VERSION ""

NS_ :

BS_:

BU_: Device Host
VAL_TABLE_ Target 0 "Other" 1 "Debug" 2 "Release" 3 "Not Available" ;
VAL_TABLE_ vtCcpExtension 1 "CcpBatchTransfer" 15 "CcpExtensionNone" ;
VAL_TABLE_ vtOnOff 0 "Off" 1 "On" 2 "Error" 3 "Not available" ;

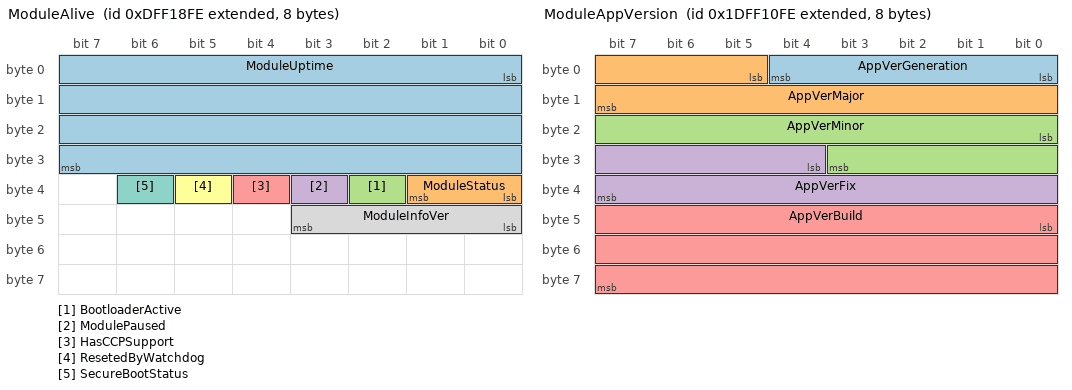
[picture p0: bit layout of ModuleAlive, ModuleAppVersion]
BO_ 2382305534 ModuleAlive: 8 Device
 SG_ ModuleUptime : 0|32@1+ (1,0) [0|4294967295] "s" Vector__XXX
 SG_ ModuleStatus : 32|2@1+ (1,0) [0|3] "" Vector__XXX
 SG_ BootloaderActive : 34|1@1+ (1,0) [0|0] "" Vector__XXX
 SG_ ModulePaused : 35|1@1+ (1,0) [0|0] "" Vector__XXX
 SG_ HasCCPSupport : 36|1@1+ (1,0) [0|0] "" Vector__XXX
 SG_ ResetedByWatchdog : 37|1@1+ (1,0) [0|1] "" Vector__XXX
 SG_ SecureBootStatus : 38|1@1+ (1,0) [0|1] "" Vector__XXX
 SG_ ModuleInfoVer : 40|4@1+ (1,0) [0|15] "" Vector__XXX

BO_ 2650739966 ModuleAppName1: 8 Device
 SG_ AppName1 : 0|64@1+ (1,0) [0|0] "" Vector__XXX

BO_ 2650740222 ModuleAppName2: 8 Device
 SG_ AppName2 : 0|64@1+ (1,0) [0|0] "" Vector__XXX

BO_ 2650738942 ModuleAppVersion: 8 Device
 SG_ AppVerGeneration : 0|5@1+ (1,0) [0|31] "" Vector__XXX
 SG_ AppVerMajor : 5|11@1+ (1,0) [0|2047] "" Vector__XXX
 SG_ AppVerMinor : 16|12@1+ (1,0) [0|4095] "" Vector__XXX
 SG_ AppVerFix : 28|12@1+ (1,0) [0|4090] "" Vector__XXX
 SG_ AppVerBuild : 40|24@1+ (1,0) [0|16777215] "" Vector__XXX

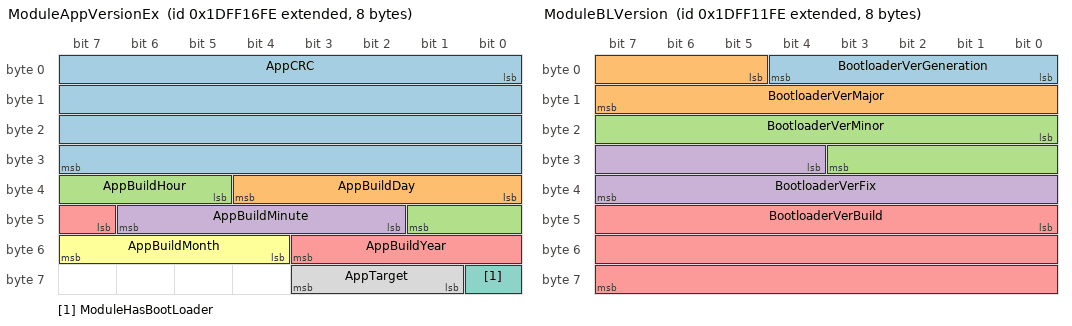
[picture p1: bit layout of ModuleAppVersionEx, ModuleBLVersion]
BO_ 2650740478 ModuleAppVersionEx: 8 Device
 SG_ AppCRC : 0|32@1+ (1,0) [0|0] "" Vector__XXX
 SG_ AppBuildDay : 32|5@1+ (1,0) [0|0] "" Vector__XXX
 SG_ AppBuildHour : 37|5@1+ (1,0) [0|0] "" Vector__XXX
 SG_ AppBuildMinute : 42|5@1+ (2,0) [0|0] "" Vector__XXX
 SG_ AppBuildYear : 47|5@1+ (1,2019) [0|0] "" Vector__XXX
 SG_ AppBuildMonth : 52|4@1+ (1,0) [0|0] "" Vector__XXX
 SG_ ModuleHasBootLoader : 56|1@1+ (1,0) [0|0] "" Vector__XXX
 SG_ AppTarget : 57|3@1+ (1,0) [0|0] "" Vector__XXX

BO_ 2650742014 ModuleBLName1: 8 Device
 SG_ BootloaderName1 : 0|64@1+ (1,0) [0|0] "" Vector__XXX

BO_ 2650741246 ModuleBLName2: 8 Device
 SG_ BootloaderName2 : 0|64@1+ (1,0) [0|0] "" Vector__XXX

BO_ 2650739198 ModuleBLVersion: 8 Device
 SG_ BootloaderVerGeneration : 0|5@1+ (1,0) [0|31] "" Vector__XXX
 SG_ BootloaderVerMajor : 5|11@1+ (1,0) [0|2047] "" Vector__XXX
 SG_ BootloaderVerMinor : 16|12@1+ (1,0) [0|4095] "" Vector__XXX
 SG_ BootloaderVerFix : 28|12@1+ (1,0) [0|4090] "" Vector__XXX
 SG_ BootloaderVerBuild : 40|24@1+ (1,0) [0|16777215] "" Vector__XXX

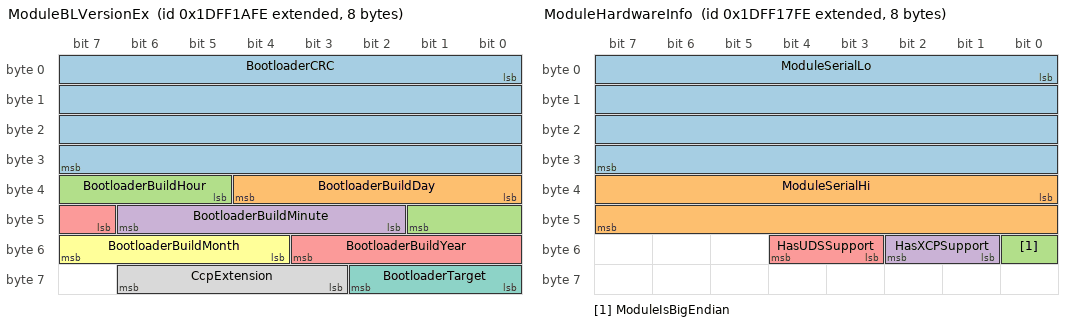
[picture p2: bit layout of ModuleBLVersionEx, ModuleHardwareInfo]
BO_ 2650741502 ModuleBLVersionEx: 8 Device
 SG_ BootloaderCRC : 0|32@1+ (1,0) [0|0] "" Vector__XXX
 SG_ BootloaderBuildDay : 32|5@1+ (1,0) [0|0] "" Vector__XXX
 SG_ BootloaderBuildHour : 37|5@1+ (1,0) [0|0] "" Vector__XXX
 SG_ BootloaderBuildMinute : 42|5@1+ (2,0) [0|0] "" Vector__XXX
 SG_ BootloaderBuildYear : 47|5@1+ (1,2019) [0|0] "" Vector__XXX
 SG_ BootloaderBuildMonth : 52|4@1+ (1,0) [0|0] "" Vector__XXX
 SG_ BootloaderTarget : 56|3@1+ (1,0) [0|0] "" Vector__XXX
 SG_ CcpExtension : 59|4@1+ (1,0) [0|0] "" Vector__XXX

BO_ 2650740734 ModuleHardwareInfo: 8 Device
 SG_ ModuleSerialLo : 0|32@1+ (1,0) [0|4294967295] "" Vector__XXX
 SG_ ModuleSerialHi : 32|16@1+ (1,0) [0|65535] "" Vector__XXX
 SG_ ModuleIsBigEndian : 48|1@1+ (1,0) [0|0] "" Vector__XXX
 SG_ HasXCPSupport : 49|2@1+ (1,0) [0|0] "" Vector__XXX
 SG_ HasUDSSupport : 51|2@1+ (1,0) [0|0] "" Vector__XXX

BO_ 2650739454 ModuleHardwareName: 8 Device
 SG_ ModuleTypeName : 0|64@1+ (1,0) [0|0] "" Vector__XXX

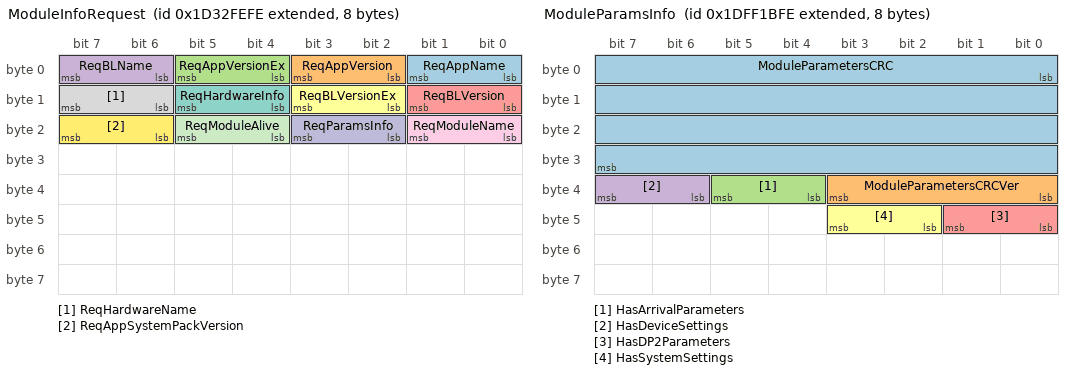
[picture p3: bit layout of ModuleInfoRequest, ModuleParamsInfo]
BO_ 2637364990 ModuleInfoRequest: 8 Host
 SG_ ReqAppName : 0|2@1+ (1,0) [0|0] "" Vector__XXX
 SG_ ReqAppVersion : 2|2@1+ (1,0) [0|0] "" Vector__XXX
 SG_ ReqAppVersionEx : 4|2@1+ (1,0) [0|0] "" Vector__XXX
 SG_ ReqBLName : 6|2@1+ (1,0) [0|0] "" Vector__XXX
 SG_ ReqBLVersion : 8|2@1+ (1,0) [0|0] "" Vector__XXX
 SG_ ReqBLVersionEx : 10|2@1+ (1,0) [0|0] "" Vector__XXX
 SG_ ReqHardwareInfo : 12|2@1+ (1,0) [0|0] "" Vector__XXX
 SG_ ReqHardwareName : 14|2@1+ (1,0) [0|0] "" Vector__XXX
 SG_ ReqModuleName : 16|2@1+ (1,0) [0|0] "" Vector__XXX
 SG_ ReqParamsInfo : 18|2@1+ (1,0) [0|0] "" Vector__XXX
 SG_ ReqModuleAlive : 20|2@1+ (1,0) [0|0] "" Vector__XXX
 SG_ ReqAppSystemPackVersion : 22|2@1+ (1,0) [0|0] "" Vector__XXX

BO_ 2650739710 ModuleName: 8 Device
 SG_ ModuleName : 0|64@1+ (1,0) [0|0] "" Vector__XXX

BO_ 2650741758 ModuleParamsInfo: 8 Device
 SG_ ModuleParametersCRC : 0|32@1+ (1,0) [0|0] "" Vector__XXX
 SG_ ModuleParametersCRCVer : 32|4@1+ (1,0) [0|15] "" Vector__XXX
 SG_ HasArrivalParameters : 36|2@1+ (1,0) [0|0] "" Vector__XXX
 SG_ HasDeviceSettings : 38|2@1+ (1,0) [0|0] "" Vector__XXX
 SG_ HasDP2Parameters : 40|2@1+ (1,0) [0|0] "" Vector__XXX
 SG_ HasSystemSettings : 42|2@1+ (1,0) [0|0] "" Vector__XXX

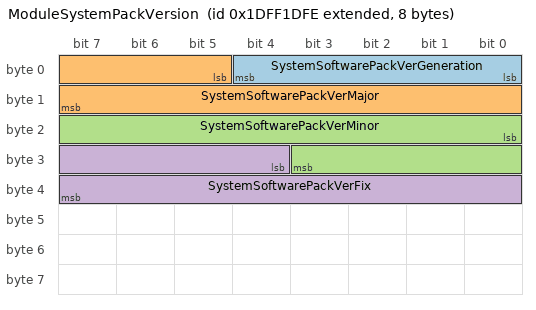
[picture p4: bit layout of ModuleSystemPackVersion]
BO_ 2650742270 ModuleSystemPackVersion: 8 Device
 SG_ SystemSoftwarePackVerGeneration : 0|5@1+ (1,0) [0|31] "" Vector__XXX
 SG_ SystemSoftwarePackVerMajor : 5|11@1+ (1,0) [0|2047] "" Vector__XXX
 SG_ SystemSoftwarePackVerMinor : 16|12@1+ (1,0) [0|4095] "" Vector__XXX
 SG_ SystemSoftwarePackVerFix : 28|12@1+ (1,0) [0|4090] "" Vector__XXX

CM_ "Module info (Versions, state, etc) messages
$File: //system_software/components/lib/module_info/0.36.0.0/dbc/module_info.dbc $
$Change: 208863 $
$DateTime: 2023/11/10 13:11:00 $
$Revision: #1 $";
CM_ BO_ 2382305534 "Information about module alive status";
CM_ SG_ 2382305534 ModuleUptime "Module uptime from last power on ";
CM_ SG_ 2382305534 ModuleStatus "Common status of module. Same value as ModuleCommonStatus";
CM_ SG_ 2382305534 BootloaderActive "Is bootloader active?";
CM_ SG_ 2382305534 ModulePaused "Set to 1 them module is paused. Usially in paused state simulink model not processed";
CM_ SG_ 2382305534 HasCCPSupport "Module has CCP (Can Calibration Protocol) support in current state (app or bootloader)";
CM_ SG_ 2382305534 ResetedByWatchdog "Indicate what module was reseted by watchdog";
CM_ SG_ 2382305534 SecureBootStatus "Indicates Secure Boot status";
CM_ SG_ 2382305534 ModuleInfoVer "Increased on every module info modification";
CM_ BO_ 2650739966 "First part of main aplication firmware name";
CM_ SG_ 2650739966 AppName1 "First part of application firmware name (chars 1..8)";
CM_ BO_ 2650740222 "Second part of main application firmware name (chars 9..16)";
CM_ SG_ 2650740222 AppName2 "Second part of application firmware name (chars 9..16)";
CM_ BO_ 2650738942 "Module main application version information";
CM_ SG_ 2650738942 AppVerGeneration "Application Generation number";
CM_ SG_ 2650738942 AppVerMajor "Application Major version number";
CM_ SG_ 2650738942 AppVerMinor "Application minor version number";
CM_ SG_ 2650738942 AppVerFix "Application fix version";
CM_ SG_ 2650738942 AppVerBuild "Application build number";
CM_ BO_ 2650740478 "Module main application version information part 2";
CM_ SG_ 2650740478 AppCRC "Application CRC32 checksum";
CM_ SG_ 2650740478 AppBuildDay "Day part of date when application was build";
CM_ SG_ 2650740478 AppBuildHour "Hour part of date when application was build";
CM_ SG_ 2650740478 AppBuildMinute "Minute part of date when application was build";
CM_ SG_ 2650740478 AppBuildYear "Year part of date when application was build";
CM_ SG_ 2650740478 AppBuildMonth "Minute part of date when application was build";
CM_ SG_ 2650740478 ModuleHasBootLoader "This module has bootloader. If firmware is monolitic set to 0";
CM_ SG_ 2650740478 AppTarget "Build target type Debug/Release. Debug builds not intended to be run on production vehicles";
CM_ BO_ 2650742014 "First part of bootloader firmware name";
CM_ SG_ 2650742014 BootloaderName1 "First part of bootloader name (chars 1..8)";
CM_ BO_ 2650741246 "Second part of bootloader firmware name (chars 9..16)";
CM_ SG_ 2650741246 BootloaderName2 "Second part of bootloader name (chars 9..16)";
CM_ BO_ 2650739198 "Module bootloader version information";
CM_ SG_ 2650739198 BootloaderVerGeneration "Bootloader Generation number";
CM_ SG_ 2650739198 BootloaderVerMajor "Bootloader Major version number";
CM_ SG_ 2650739198 BootloaderVerMinor "Bootloader minor version number";
CM_ SG_ 2650739198 BootloaderVerFix "Bootloader fix version";
CM_ SG_ 2650739198 BootloaderVerBuild "Bootloader build number";
CM_ BO_ 2650741502 "Module bootloader version information part 2";
CM_ SG_ 2650741502 BootloaderCRC "Bootloader CRC32 checksum";
CM_ SG_ 2650741502 BootloaderBuildDay "Day part of date when bootloader was build";
CM_ SG_ 2650741502 BootloaderBuildHour "Hour part of date when bootloader was build";
CM_ SG_ 2650741502 BootloaderBuildMinute "Minute part of date when bootloader was build";
CM_ SG_ 2650741502 BootloaderBuildYear "Year part of date when bootloader was build";
CM_ SG_ 2650741502 BootloaderBuildMonth "Month part of date when bootloader was build";
CM_ SG_ 2650741502 BootloaderTarget "Build target type Debug/Release. Debug builds not intended to be run on production vehicles";
CM_ BO_ 2650740734 "Module hardware information and capabalities";
CM_ SG_ 2650740734 ModuleSerialLo "Unique serial number of device";
CM_ SG_ 2650740734 ModuleSerialHi "Unique serial number of device";
CM_ SG_ 2650740734 ModuleIsBigEndian "Module MCU is bigendian. This flasg is used to encode variables in CCP";
CM_ SG_ 2650740734 HasXCPSupport "Module has XCP (eXtended Calibration Protocol) support in current state (app or bootloader)";
CM_ SG_ 2650740734 HasUDSSupport "Module has UDS (Unified Diagnostics Services) support in current state (app or bootloader)";
CM_ BO_ 2650739454 "Module hardware (PCB) name";
CM_ SG_ 2650739454 ModuleTypeName "Device Type Name. Different names can be assigned to every device type (PCB Revision)";
CM_ BO_ 2637364990 "Request to send module information messages";
CM_ SG_ 2637364990 ReqAppName "Request to send ModuleAppName1 & ModuleAppName2 messages ";
CM_ SG_ 2637364990 ReqAppVersion "Request to send ModuleAppVersion message";
CM_ SG_ 2637364990 ReqAppVersionEx "Request to send ModuleAppVersionEx message";
CM_ SG_ 2637364990 ReqBLName "Request to send ModuleBLName1 & ModuleBLName2 messages ";
CM_ SG_ 2637364990 ReqBLVersion "Request to send ModuleBLVersion message";
CM_ SG_ 2637364990 ReqBLVersionEx "Request to send ModuleBLVersionEx message";
CM_ SG_ 2637364990 ReqHardwareInfo "Request to send ModuleHardwareInfo message";
CM_ SG_ 2637364990 ReqHardwareName "Request to send ModuleHardwareName message";
CM_ SG_ 2637364990 ReqModuleName "Request to send ModuleName message";
CM_ SG_ 2637364990 ReqParamsInfo "Request to send ModuleParamsInfo message";
CM_ SG_ 2637364990 ReqModuleAlive "Request to send ModuleAlive message";
CM_ SG_ 2637364990 ReqAppSystemPackVersion "Request to send ModuleSystemPackVersion message";
CM_ BO_ 2650739710 "Module user friendly name. Can be set for every module instance parameters. Usefull for debuging";
CM_ SG_ 2650739710 ModuleName "Module Name. Different names can be assigned to every module";
CM_ BO_ 2650741758 "Information about current module working set parameters. This is common CRC32 of all parameters: System Settings, Device Settings, DP2/OfflineOnly,  Arrival Parameters";
CM_ SG_ 2650741758 ModuleParametersCRC "CRC32 of parameters working set";
CM_ SG_ 2650741758 ModuleParametersCRCVer "Increased on every parameters modification (copy from edit to working set)";
CM_ SG_ 2650741758 HasArrivalParameters "Current active firmware (application or bootloader) has Arrival (old) parameters";
CM_ SG_ 2650741758 HasDeviceSettings "Current active firmware (application or bootloader) has Device Settings";
CM_ SG_ 2650741758 HasDP2Parameters "Current active firmware (application or bootloader) has DP2 or OFFLINE_ONLY parameters";
CM_ SG_ 2650741758 HasSystemSettings "Current active firmware (application or bootloader) has System Settings";
CM_ BO_ 2650742270 "System Software Pack version information";
CM_ SG_ 2650742270 SystemSoftwarePackVerGeneration "System Software Pack Generation number";
CM_ SG_ 2650742270 SystemSoftwarePackVerMajor "System Software Pack Major version number";
CM_ SG_ 2650742270 SystemSoftwarePackVerMinor "System Software Pack minor version number";
CM_ SG_ 2650742270 SystemSoftwarePackVerFix "System Software Pack fix version";
BA_DEF_  "BusType" STRING ;
BA_DEF_  "DBName" STRING ;
BA_DEF_ BO_ "GenMsgCycleTime" INT 0 65535;
BA_DEF_ BO_ "GenMsgILSupport" ENUM  "No","Yes";
BA_DEF_ BO_ "GenMsgRequestable" INT 0 1;
BA_DEF_ BO_ "GenMsgSendType" ENUM  "cyclic","NotUsed","NotUsed","NotUsed","NotUsed","NotUsed","NotUsed","IfActive","noMsgSendType";
BA_DEF_ SG_ "GenSigEVName" STRING ;
BA_DEF_ SG_ "GenSigILSupport" ENUM  "No","Yes";
BA_DEF_ SG_ "GenSigSendType" ENUM  "Cyclic","OnWrite","OnWriteWithRepetition","OnChange","OnChangeWithRepetition","IfActive","IfActiveWithRepetition","NoSigSendType";
BA_DEF_ SG_ "GenSigStartValue" FLOAT -3.4e+38 3.4e+38;
BA_DEF_ BU_ "NmStationAddress" INT 0 255;
BA_DEF_  "ProtocolType" STRING ;
BA_DEF_ SG_ "SPN" INT 0 524287;
BA_DEF_ BO_ "SendOnChange" ENUM  "No","Yes";
BA_DEF_ SG_ "SigType" ENUM  "Default","Range","RangeSigned","ASCII","Discrete","Control","ReferencePGN","DTC","StringDelimiter","StringLength","StringLengthControl","MessageCounter","MessageChecksum";
BA_DEF_ BO_ "VFrameFormat" ENUM  "StandardCAN","ExtendedCAN","reserved","J1939PG";
BA_DEF_DEF_  "BusType" "CAN";
BA_DEF_DEF_  "DBName" "";
BA_DEF_DEF_  "GenMsgCycleTime" 0;
BA_DEF_DEF_  "GenMsgILSupport" "Yes";
BA_DEF_DEF_  "GenMsgRequestable" 1;
BA_DEF_DEF_  "GenMsgSendType" "noMsgSendType";
BA_DEF_DEF_  "GenSigEVName" "Env@Nodename_@Signame";
BA_DEF_DEF_  "GenSigILSupport" "Yes";
BA_DEF_DEF_  "GenSigSendType" "NoSigSendType";
BA_DEF_DEF_  "GenSigStartValue" 0;
BA_DEF_DEF_  "NmStationAddress" 254;
BA_DEF_DEF_  "ProtocolType" "";
BA_DEF_DEF_  "SPN" 0;
BA_DEF_DEF_  "SendOnChange" "No";
BA_DEF_DEF_  "SigType" "Default";
BA_DEF_DEF_  "VFrameFormat" "J1939PG";
BA_ "DBName" "module_info";
BA_ "ProtocolType" "J1939";
BA_ "GenMsgCycleTime" BO_ 2382305534 100;
BA_ "GenMsgRequestable" BO_ 2382305534 0;
BA_ "GenMsgSendType" BO_ 2382305534 0;
BA_ "GenMsgRequestable" BO_ 2650739966 0;
BA_ "GenMsgRequestable" BO_ 2650740222 0;
BA_ "GenMsgRequestable" BO_ 2650738942 0;
BA_ "GenMsgRequestable" BO_ 2650740478 0;
BA_ "GenMsgRequestable" BO_ 2650742014 0;
BA_ "GenMsgRequestable" BO_ 2650741246 0;
BA_ "GenMsgRequestable" BO_ 2650739198 0;
BA_ "GenMsgRequestable" BO_ 2650741502 0;
BA_ "GenMsgRequestable" BO_ 2650740734 0;
BA_ "GenMsgRequestable" BO_ 2650739454 0;
BA_ "GenMsgRequestable" BO_ 2637364990 0;
BA_ "SendOnChange" BO_ 2650739710 1;
BA_ "SendOnChange" BO_ 2650741758 1;
BA_ "GenMsgRequestable" BO_ 2650742270 0;
BA_ "SPN" SG_ 2382305534 ModuleUptime 519366;
BA_ "GenSigStartValue" SG_ 2382305534 ModuleStatus 3;
BA_ "SPN" SG_ 2382305534 ModuleStatus 519367;
BA_ "SPN" SG_ 2382305534 BootloaderActive 519368;
BA_ "SPN" SG_ 2382305534 ModulePaused 519369;
BA_ "SPN" SG_ 2382305534 HasCCPSupport 519370;
BA_ "SPN" SG_ 2382305534 ResetedByWatchdog 519364;
BA_ "SPN" SG_ 2382305534 SecureBootStatus 516000;
BA_ "SPN" SG_ 2382305534 ModuleInfoVer 519371;
BA_ "SPN" SG_ 2650739966 AppName1 519372;
BA_ "SigType" SG_ 2650739966 AppName1 3;
BA_ "SPN" SG_ 2650740222 AppName2 519373;
BA_ "SigType" SG_ 2650740222 AppName2 3;
BA_ "SPN" SG_ 2650738942 AppVerGeneration 519374;
BA_ "SPN" SG_ 2650738942 AppVerMajor 519375;
BA_ "SPN" SG_ 2650738942 AppVerMinor 519376;
BA_ "SPN" SG_ 2650738942 AppVerFix 519377;
BA_ "SPN" SG_ 2650738942 AppVerBuild 519378;
BA_ "SPN" SG_ 2650740478 AppCRC 519365;
BA_ "SPN" SG_ 2650740478 AppBuildDay 519379;
BA_ "SPN" SG_ 2650740478 AppBuildHour 519380;
BA_ "SPN" SG_ 2650740478 AppBuildMinute 519381;
BA_ "SPN" SG_ 2650740478 AppBuildYear 519382;
BA_ "SPN" SG_ 2650740478 AppBuildMonth 519383;
BA_ "SPN" SG_ 2650740478 ModuleHasBootLoader 519384;
BA_ "GenSigStartValue" SG_ 2650740478 AppTarget 7;
BA_ "SPN" SG_ 2650740478 AppTarget 519385;
BA_ "SPN" SG_ 2650742014 BootloaderName1 519386;
BA_ "SigType" SG_ 2650742014 BootloaderName1 3;
BA_ "SPN" SG_ 2650741246 BootloaderName2 519387;
BA_ "SigType" SG_ 2650741246 BootloaderName2 3;
BA_ "SPN" SG_ 2650739198 BootloaderVerGeneration 519388;
BA_ "SPN" SG_ 2650739198 BootloaderVerMajor 519389;
BA_ "SPN" SG_ 2650739198 BootloaderVerMinor 519390;
BA_ "SPN" SG_ 2650739198 BootloaderVerFix 519391;
BA_ "SPN" SG_ 2650739198 BootloaderVerBuild 519392;
BA_ "SPN" SG_ 2650741502 BootloaderCRC 519393;
BA_ "SPN" SG_ 2650741502 BootloaderBuildDay 519394;
BA_ "SPN" SG_ 2650741502 BootloaderBuildHour 519395;
BA_ "SPN" SG_ 2650741502 BootloaderBuildMinute 519396;
BA_ "SPN" SG_ 2650741502 BootloaderBuildYear 519397;
BA_ "SPN" SG_ 2650741502 BootloaderBuildMonth 519398;
BA_ "GenSigStartValue" SG_ 2650741502 BootloaderTarget 7;
BA_ "SPN" SG_ 2650741502 BootloaderTarget 519399;
BA_ "SPN" SG_ 2650741502 CcpExtension 519450;
BA_ "SPN" SG_ 2650740734 ModuleSerialLo 519451;
BA_ "SPN" SG_ 2650740734 ModuleSerialHi 519452;
BA_ "SPN" SG_ 2650740734 ModuleIsBigEndian 519453;
BA_ "SPN" SG_ 2650740734 HasXCPSupport 519454;
BA_ "SPN" SG_ 2650740734 HasUDSSupport 519470;
BA_ "SPN" SG_ 2650739454 ModuleTypeName 519455;
BA_ "SigType" SG_ 2650739454 ModuleTypeName 3;
BA_ "GenSigStartValue" SG_ 2637364990 ReqAppName 1;
BA_ "SPN" SG_ 2637364990 ReqAppName 519456;
BA_ "GenSigStartValue" SG_ 2637364990 ReqAppVersion 1;
BA_ "SPN" SG_ 2637364990 ReqAppVersion 519457;
BA_ "GenSigStartValue" SG_ 2637364990 ReqAppVersionEx 1;
BA_ "SPN" SG_ 2637364990 ReqAppVersionEx 519458;
BA_ "GenSigStartValue" SG_ 2637364990 ReqBLName 1;
BA_ "SPN" SG_ 2637364990 ReqBLName 519459;
BA_ "GenSigStartValue" SG_ 2637364990 ReqBLVersion 1;
BA_ "SPN" SG_ 2637364990 ReqBLVersion 519460;
BA_ "GenSigStartValue" SG_ 2637364990 ReqBLVersionEx 1;
BA_ "SPN" SG_ 2637364990 ReqBLVersionEx 519461;
BA_ "GenSigStartValue" SG_ 2637364990 ReqHardwareInfo 1;
BA_ "SPN" SG_ 2637364990 ReqHardwareInfo 519462;
BA_ "GenSigStartValue" SG_ 2637364990 ReqHardwareName 1;
BA_ "SPN" SG_ 2637364990 ReqHardwareName 519463;
BA_ "GenSigStartValue" SG_ 2637364990 ReqModuleName 1;
BA_ "SPN" SG_ 2637364990 ReqModuleName 519464;
BA_ "GenSigStartValue" SG_ 2637364990 ReqParamsInfo 1;
BA_ "SPN" SG_ 2637364990 ReqParamsInfo 519465;
BA_ "GenSigStartValue" SG_ 2637364990 ReqModuleAlive 1;
BA_ "SPN" SG_ 2637364990 ReqModuleAlive 519466;
BA_ "GenSigStartValue" SG_ 2637364990 ReqAppSystemPackVersion 1;
BA_ "SPN" SG_ 2637364990 ReqAppSystemPackVersion 519471;
BA_ "SPN" SG_ 2650739710 ModuleName 519467;
BA_ "SigType" SG_ 2650739710 ModuleName 3;
BA_ "SPN" SG_ 2650741758 ModuleParametersCRC 519468;
BA_ "SPN" SG_ 2650741758 ModuleParametersCRCVer 519469;
BA_ "SPN" SG_ 2650742270 SystemSoftwarePackVerGeneration 519472;
BA_ "SPN" SG_ 2650742270 SystemSoftwarePackVerMajor 519473;
BA_ "SPN" SG_ 2650742270 SystemSoftwarePackVerMinor 519474;
BA_ "SPN" SG_ 2650742270 SystemSoftwarePackVerFix 519475;
VAL_ 2382305534 ModuleStatus 0 "Ok" 1 "Warning" 2 "Critical" 3 "Not Available" ;
VAL_ 2650740478 AppTarget 1 "DebugCheck" 2 "ReleaseCheck" 4 "Other" 5 "Debug" 6 "Release" 7 "Not Available" ;
VAL_ 2650741502 BootloaderTarget 1 "Other" 2 "DebugCheck" 3 "Debug" 4 "ReleaseCheck" 5 "Release" 7 "Not Available" ;
VAL_ 2650741502 CcpExtension 0 "Reserved" 1 "CcpBatchTransfer" 15 "CcpExtensionNone" ;
VAL_ 2650740734 HasXCPSupport 0 "Off" 1 "On" 2 "Error" 3 "Not available" ;
VAL_ 2650740734 HasUDSSupport 0 "Off" 1 "On" 2 "Error" 3 "Not available" ;
VAL_ 2637364990 ReqAppName 0 "Off" 1 "On" 2 "Error" 3 "Not available" ;
VAL_ 2637364990 ReqAppVersion 0 "Off" 1 "On" 2 "Error" 3 "Not available" ;
VAL_ 2637364990 ReqAppVersionEx 0 "Off" 1 "On" 2 "Error" 3 "Not available" ;
VAL_ 2637364990 ReqBLName 0 "Off" 1 "On" 2 "Error" 3 "Not available" ;
VAL_ 2637364990 ReqBLVersion 0 "Off" 1 "On" 2 "Error" 3 "Not available" ;
VAL_ 2637364990 ReqBLVersionEx 0 "Off" 1 "On" 2 "Error" 3 "Not available" ;
VAL_ 2637364990 ReqHardwareInfo 0 "Off" 1 "On" 2 "Error" 3 "Not available" ;
VAL_ 2637364990 ReqHardwareName 0 "Off" 1 "On" 2 "Error" 3 "Not available" ;
VAL_ 2637364990 ReqModuleName 0 "Off" 1 "On" 2 "Error" 3 "Not available" ;
VAL_ 2637364990 ReqParamsInfo 0 "Off" 1 "On" 2 "Error" 3 "Not available" ;
VAL_ 2637364990 ReqModuleAlive 0 "Off" 1 "On" 2 "Error" 3 "Not available" ;
VAL_ 2637364990 ReqAppSystemPackVersion 0 "Off" 1 "On" 2 "Error" 3 "Not available" ;
VAL_ 2650741758 HasArrivalParameters 0 "Off" 1 "On" 2 "Error" 3 "Not available" ;
VAL_ 2650741758 HasDeviceSettings 0 "Off" 1 "On" 2 "Error" 3 "Not available" ;
VAL_ 2650741758 HasDP2Parameters 0 "Off" 1 "On" 2 "Error" 3 "Not available" ;
VAL_ 2650741758 HasSystemSettings 0 "Off" 1 "On" 2 "Error" 3 "Not available" ;
